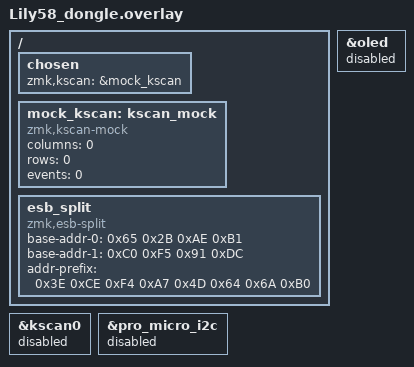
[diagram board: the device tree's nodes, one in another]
/*
 * Copyright (c) 2020 Pete Johanson
 *
 * SPDX-License-Identifier: MIT
 */

// Reuse the real Lily58 matrix-transform/physical-layout/keymap unchanged -
// the central needs the full two-handed layout to interpret position
// events coming in from both ESB peripherals.
#include "../Lily58/Lily58.dtsi"

/ {
    chosen {
        zmk,kscan = &mock_kscan;
        /delete-property/ zephyr,display;
    };

    // The dongle has no physical keys of its own.
    mock_kscan: kscan_mock {
        compatible = "zmk,kscan-mock";
        columns = <0>;
        rows = <0>;
        events = <0>;
    };
};

// Lily58.dtsi's kscan0 only has row-gpios; col-gpios are added per-half by
// Lily58_L/R.overlay. The dongle isn't wired to a matrix at all, so disable
// it rather than leave it incomplete.
&kscan0 {
    status = "disabled";
};

// No OLED/nice!view hardware on the dongle board.
&pro_micro_i2c {
    status = "disabled";
};

&oled {
    status = "disabled";
};

// ESB arbitrary addresses - MUST be byte-identical across the dongle and
// both peripherals (Lily58_L.overlay / Lily58_R.overlay).
/ {
    esb_split {
        compatible = "zmk,esb-split";
        base-addr-0 = <0x65 0x2B 0xAE 0xB1>;
        base-addr-1 = <0xC0 0xF5 0x91 0xDC>;
        addr-prefix = <0x3E 0xCE 0xF4 0xA7 0x4D 0x64 0x6A 0xB0>;
    };
};
